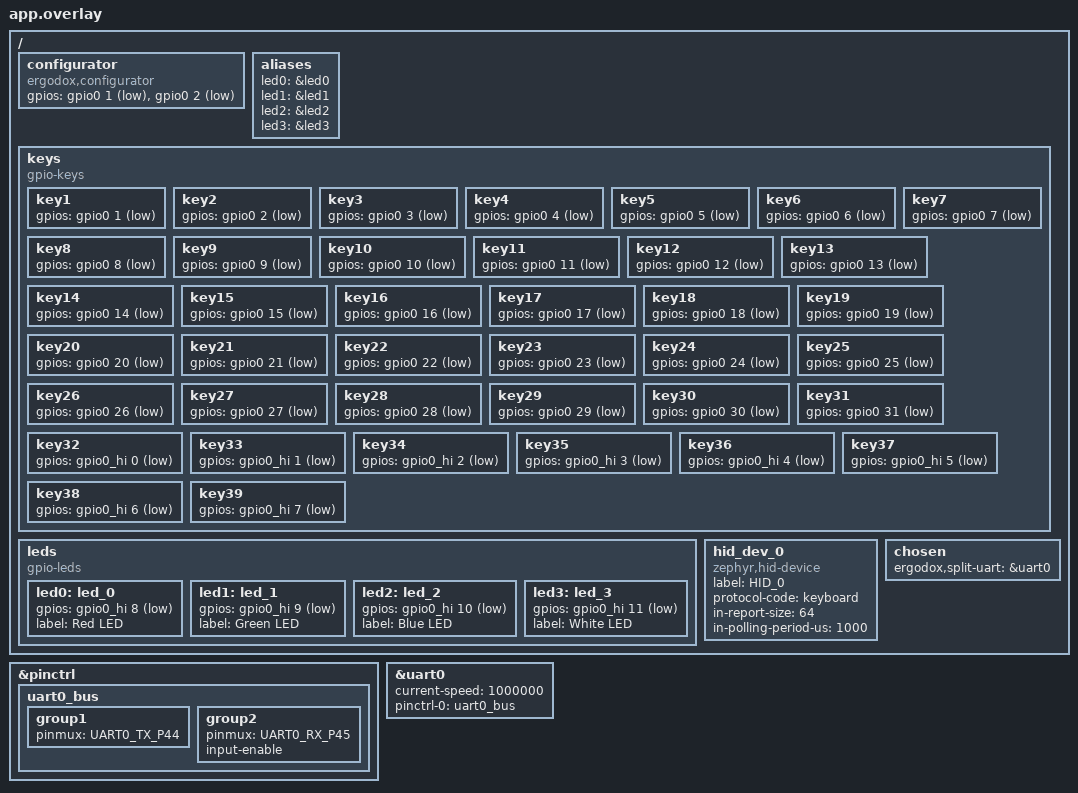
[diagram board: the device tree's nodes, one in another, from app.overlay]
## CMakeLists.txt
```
cmake_minimum_required(VERSION 3.20.0)

set(BOARD rp2350b_core/rp2350b/m33)
set(ERGODOX_SOURCE_DIR "${CMAKE_CURRENT_LIST_DIR}")

# Discover application bindings even when sysbuild uses its image directory.
list(APPEND DTS_ROOT "${ERGODOX_SOURCE_DIR}")

find_package(Zephyr REQUIRED)
project(ergodoxcustom)

include(${ERGODOX_SOURCE_DIR}/cmake/ergodox_application.cmake)
```

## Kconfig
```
mainmenu "Ergodox custom main menu"

choice ERGODOX_KEYBOARD_HAND
    prompt "Keyboard hand"
    default ERGODOX_KEYBOARD_HAND_RIGHT

config ERGODOX_KEYBOARD_HAND_LEFT
    bool "Left hand"
    help
      Build firmware using the left-hand side of the selected layout.

config ERGODOX_KEYBOARD_HAND_RIGHT
    bool "Right hand"
    help
      Build firmware using the right-hand side of the selected layout.

endchoice

config ERGODOX_SPLIT_UART
    bool "Enable split keyboard UART transport"
    default y
    select SERIAL
    select UART_INTERRUPT_DRIVEN
    help
      Enable the UART transport used to forward raw key events from the
      non-USB half to the USB-connected half.

config ERGODOX_SPLIT_UART_BAUDRATE
    int "Split UART baudrate"
    default 1000000
    depends on ERGODOX_SPLIT_UART

config ERGODOX_USB_READY_TIMEOUT_MS
    int "USB ready timeout before falling back to UART"
    default 1500
    help
      Time to wait at boot for the USB HID interface to become ready. If USB
      initialization fails or the interface is not ready before this timeout,
      the firmware acts as the UART-sender half.

choice ERGODOX_KEYBOARD_LAYOUT
    prompt "Factory fallback keyboard layout"
    default ERGODOX_KEYBOARD_LAYOUT_SIMPLE

config ERGODOX_KEYBOARD_LAYOUT_SIMPLE
    bool "Simple layered layout"
    help
      Factory fallback used when NVM has no valid configuration.
      QWERTY-style layout with navigation, symbol, and function layers.

config ERGODOX_KEYBOARD_LAYOUT_CUSTOM
    bool "My custom layout"
    help
      Compiled custom factory fallback used when NVM has no valid configuration.

endchoice

source "Kconfig.zephyr"
```

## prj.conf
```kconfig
CONFIG_USB_DEVICE_STACK_NEXT=y
CONFIG_USBD_HID_SUPPORT=y

CONFIG_GPIO=y

CONFIG_MAIN_STACK_SIZE=4096

CONFIG_LOG=y
CONFIG_LOG_DEFAULT_LEVEL=3

# Stream logs over SWD using RTT channel 0 (Raspberry Pi Debug Probe/OpenOCD).
CONFIG_USE_SEGGER_RTT=y
CONFIG_LOG_BACKEND_RTT=y
CONFIG_LOG_BACKEND_RTT_BUFFER=0
CONFIG_LOG_BACKEND_RTT_MODE_DROP=y
CONFIG_SEGGER_RTT_MODE_NO_BLOCK_SKIP=y
CONFIG_SEGGER_RTT_BUFFER_SIZE_UP=4096

# Keep USB CDC ACM serial initialization disabled
CONFIG_UDC_RPI_PICO=y
CONFIG_USB_CDC_ACM=n
CONFIG_CDC_ACM_SERIAL_INITIALIZE_AT_BOOT=n

CONFIG_UART_CONSOLE=n
CONFIG_LOG_BACKEND_UART=n

CONFIG_NUM_PREEMPT_PRIORITIES=6

CONFIG_ERGODOX_SPLIT_UART=y
CONFIG_ERGODOX_KEYBOARD_LAYOUT_CUSTOM=y

# USB networking is registered only when the boot chord selects configurator mode.
CONFIG_NETWORKING=y
CONFIG_NET_L2_ETHERNET=y
CONFIG_NET_IPV4=y
CONFIG_NET_IPV6=n
CONFIG_NET_TCP=y
CONFIG_NET_UDP=y
CONFIG_NET_DHCPV4_SERVER=y
CONFIG_NET_DHCPV4_SERVER_ADDR_COUNT=1
CONFIG_NET_DHCPV4_SERVER_OPTION_ROUTER=n
CONFIG_NET_DHCPV4_SERVER_OPTION_DNS_ADDRESS=""
CONFIG_HTTP_SERVER=y
CONFIG_HTTP_SERVER_VERSION_2=n
# HTTP/1.1 upload validation reads Content-Type through header capture.
CONFIG_HTTP_SERVER_CAPTURE_HEADERS=y
CONFIG_HTTP_SERVER_CAPTURE_HEADER_COUNT=1
CONFIG_HTTP_SERVER_CAPTURE_HEADER_BUFFER_SIZE=64
# Browsers can keep six connections open to one HTTP origin.
CONFIG_HTTP_SERVER_MAX_CLIENTS=6
CONFIG_NET_MAX_CONTEXTS=12
CONFIG_NET_MAX_CONN=16
CONFIG_ZVFS_POLL_MAX=12
CONFIG_NET_TCP_MAX_SEND_WINDOW_SIZE=2048
CONFIG_NET_TCP_MAX_RECV_WINDOW_SIZE=2048
CONFIG_NET_LOG=y
CONFIG_NET_HTTP_SERVER_LOG_LEVEL_INF=y
CONFIG_HTTP_SERVER_CLIENT_BUFFER_SIZE=1024
CONFIG_NET_PKT_RX_COUNT=16
CONFIG_NET_PKT_TX_COUNT=16
CONFIG_NET_BUF_DATA_SIZE=256
CONFIG_NET_BUF_RX_COUNT=96
CONFIG_NET_BUF_TX_COUNT=96

# One versioned binary configuration record in a dedicated 16 KiB partition.
CONFIG_FLASH=y
CONFIG_FLASH_MAP=y
CONFIG_FLASH_PAGE_LAYOUT=y
CONFIG_NVS=y
```

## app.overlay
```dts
/ {
    configurator {
        compatible = "ergodox,configurator";
        // Hold physical keys 1 and 2 on this half while powering up.
        gpios = <&gpio0 1 (GPIO_ACTIVE_LOW | GPIO_PULL_UP)>,
                <&gpio0 2 (GPIO_ACTIVE_LOW | GPIO_PULL_UP)>;
    };

    aliases {
        led0 = &led0;
        led1 = &led1;
        led2 = &led2;
        led3 = &led3;
    };

    // Define keyboard key GPIOs
    keys: keys {
        compatible = "gpio-keys";

        key1: key1 { gpios = <&gpio0 1 GPIO_ACTIVE_LOW>; };
        key2: key2 { gpios = <&gpio0 2 GPIO_ACTIVE_LOW>; };
        key3: key3 { gpios = <&gpio0 3 GPIO_ACTIVE_LOW>; };
        key4: key4 { gpios = <&gpio0 4 GPIO_ACTIVE_LOW>; };
        key5: key5 { gpios = <&gpio0 5 GPIO_ACTIVE_LOW>; };
        key6: key6 { gpios = <&gpio0 6 GPIO_ACTIVE_LOW>; };
        key7: key7 { gpios = <&gpio0 7 GPIO_ACTIVE_LOW>; };
        key8: key8 { gpios = <&gpio0 8 GPIO_ACTIVE_LOW>; };
        key9: key9 { gpios = <&gpio0 9 GPIO_ACTIVE_LOW>; };
        key10: key10 { gpios = <&gpio0 10 GPIO_ACTIVE_LOW>; };
        key11: key11 { gpios = <&gpio0 11 GPIO_ACTIVE_LOW>; };
        key12: key12 { gpios = <&gpio0 12 GPIO_ACTIVE_LOW>; };
        key13: key13 { gpios = <&gpio0 13 GPIO_ACTIVE_LOW>; };
        key14: key14 { gpios = <&gpio0 14 GPIO_ACTIVE_LOW>; };
        key15: key15 { gpios = <&gpio0 15 GPIO_ACTIVE_LOW>; };
        key16: key16 { gpios = <&gpio0 16 GPIO_ACTIVE_LOW>; };
        key17: key17 { gpios = <&gpio0 17 GPIO_ACTIVE_LOW>; };
        key18: key18 { gpios = <&gpio0 18 GPIO_ACTIVE_LOW>; };
        key19: key19 { gpios = <&gpio0 19 GPIO_ACTIVE_LOW>; };
        key20: key20 { gpios = <&gpio0 20 GPIO_ACTIVE_LOW>; };
        key21: key21 { gpios = <&gpio0 21 GPIO_ACTIVE_LOW>; };
        key22: key22 { gpios = <&gpio0 22 GPIO_ACTIVE_LOW>; };
        key23: key23 { gpios = <&gpio0 23 GPIO_ACTIVE_LOW>; };
        key24: key24 { gpios = <&gpio0 24 GPIO_ACTIVE_LOW>; };
        key25: key25 { gpios = <&gpio0 25 GPIO_ACTIVE_LOW>; };
        key26: key26 { gpios = <&gpio0 26 GPIO_ACTIVE_LOW>; };
        key27: key27 { gpios = <&gpio0 27 GPIO_ACTIVE_LOW>; };
        key28: key28 { gpios = <&gpio0 28 GPIO_ACTIVE_LOW>; };
        key29: key29 { gpios = <&gpio0 29 GPIO_ACTIVE_LOW>; };
        key30: key30 { gpios = <&gpio0 30 GPIO_ACTIVE_LOW>; };
        key31: key31 { gpios = <&gpio0 31 GPIO_ACTIVE_LOW>; };
        key32: key32 { gpios = <&gpio0_hi 0 GPIO_ACTIVE_LOW>; };
        key33: key33 { gpios = <&gpio0_hi 1 GPIO_ACTIVE_LOW>; };
        key34: key34 { gpios = <&gpio0_hi 2 GPIO_ACTIVE_LOW>; };
        key35: key35 { gpios = <&gpio0_hi 3 GPIO_ACTIVE_LOW>; };
        key36: key36 { gpios = <&gpio0_hi 4 GPIO_ACTIVE_LOW>; };
        key37: key37 { gpios = <&gpio0_hi 5 GPIO_ACTIVE_LOW>; };
        key38: key38 { gpios = <&gpio0_hi 6 GPIO_ACTIVE_LOW>; };
        key39: key39 { gpios = <&gpio0_hi 7 GPIO_ACTIVE_LOW>; };
    };

    leds {
        compatible = "gpio-leds";
        led0: led_0 {
            gpios = <&gpio0_hi 8 GPIO_ACTIVE_LOW>;
            label = "Red LED";
        };
        led1: led_1 {
            gpios = <&gpio0_hi 9 GPIO_ACTIVE_LOW>;
            label = "Green LED";
        };
        led2: led_2 {
            gpios = <&gpio0_hi 10 GPIO_ACTIVE_LOW>;
            label = "Blue LED";
        };
        led3: led_3 {
            gpios = <&gpio0_hi 11 GPIO_ACTIVE_LOW>;
            label = "White LED";
        };
    };

    hid_dev_0: hid_dev_0 {
		compatible = "zephyr,hid-device";
		label = "HID_0";
		protocol-code = "keyboard";
		in-report-size = <64>;
		in-polling-period-us = <1000>;
	};


	chosen {
	    ergodox,split-uart = &uart0;
	    // zephyr,console = &uart0;
	    // zephyr,shell-uart = &uart0;
	};
};


&pinctrl {
    uart0_bus: uart0_bus {
        group1 {
            pinmux = <UART0_TX_P44>;
        };
        group2 {
            pinmux = <UART0_RX_P45>;
            input-enable;
        };
    };
};

&uart0 {
    status = "okay";
    current-speed = <1000000>;
    pinctrl-0 = <&uart0_bus>;
    pinctrl-names = "default";
};
```

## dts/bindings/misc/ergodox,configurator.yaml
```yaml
description: Boot chord for entering the ErgoDox configurator
compatible: "ergodox,configurator"
properties:
  gpios:
    type: phandle-array
    required: true
    description: |
      Local GPIO inputs which must all be logically active throughout the boot
      sampling interval. Specify polarity and pull resistors in each GPIO entry.
      These may share pins with keyboard keys. An empty list is not permitted.
```

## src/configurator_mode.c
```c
#include <errno.h>

#include <zephyr/drivers/gpio.h>
#include <zephyr/kernel.h>
#include <zephyr/logging/log.h>

#include "configurator_mode.h"
#include "configurator_network.h"
#include "keyboard_config.h"
#include "keyboard_input_state.h"

LOG_MODULE_REGISTER(configurator);

#define CONFIGURATOR_NODE DT_COMPAT_GET_ANY_STATUS_OKAY(ergodox_configurator)

BUILD_ASSERT(DT_NUM_INST_STATUS_OKAY(ergodox_configurator) <= 1,
    "Only one configurator boot chord may be defined");

#if DT_HAS_COMPAT_STATUS_OKAY(ergodox_configurator)
#define CHORD_GPIO(node_id, prop, idx) GPIO_DT_SPEC_GET_BY_IDX(node_id, prop, idx),
static const struct gpio_dt_spec chord[] = {
    DT_FOREACH_PROP_ELEM(CONFIGURATOR_NODE, gpios, CHORD_GPIO)
};
BUILD_ASSERT(ARRAY_SIZE(chord) > 0, "Configurator chord must not be empty");
#endif

int configurator_mode_requested(bool *requested)
{
    *requested = false;
#if DT_HAS_COMPAT_STATUS_OKAY(ergodox_configurator)
    for (size_t i = 0; i < ARRAY_SIZE(chord); ++i) {
        if (!gpio_is_ready_dt(&chord[i])) {
            return -ENODEV;
        }
        int ret = gpio_pin_configure_dt(&chord[i], GPIO_INPUT);
        if (ret < 0) {
            return ret;
        }
    }

    /* Allow pulls to settle, then require the entire chord for 20 ms. */
    k_sleep(K_MSEC(1));
    for (int sample = 0; sample <= 4; ++sample) {
        for (size_t i = 0; i < ARRAY_SIZE(chord); ++i) {
            int ret = gpio_pin_get_dt(&chord[i]);
            if (ret < 0) {
                return ret;
            }
            if (ret == 0) {
                return 0;
            }
        }
        if (sample < 4) {
            k_sleep(K_MSEC(5));
        }
    }
    *requested = true;
#endif
    return 0;
}

void configurator_mode_run(void)
{
    int ret = keyboard_config_init(true);

    if (ret == 0) {
        ret = keyboard_inputs_start_configurator();
    }
    if (ret == 0) {
        ret = configurator_network_start();
    }

    if (ret != 0) {
        LOG_ERR("Configurator startup failed: %d; reboot to retry", ret);
    }
    for (;;) {
        k_sleep(K_FOREVER);
    }
}
```

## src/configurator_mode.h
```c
#ifndef ERGODOX_CONFIGURATOR_MODE_H
#define ERGODOX_CONFIGURATOR_MODE_H

#include <stdbool.h>

/* Returns zero and the boot decision, or a negative GPIO error. */
int configurator_mode_requested(bool *requested);
/* Placeholder until USB networking and the configuration server are added. */
void configurator_mode_run(void);

#endif
```

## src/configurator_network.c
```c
#include <errno.h>
#include <string.h>
#include <strings.h>

#include <zephyr/device.h>
#include <zephyr/kernel.h>
#include <zephyr/logging/log.h>
#include <zephyr/net/dhcpv4_server.h>
#include <zephyr/net/http/server.h>
#include <zephyr/net/http/service.h>
#include <zephyr/net/net_if.h>
#include <zephyr/usb/usbd.h>

#include "configurator_network.h"
#include "keyboard_config.h"
#include "keyboard_input_state.h"

LOG_MODULE_REGISTER(configurator_network);

#define CONFIGURATOR_ADDRESS "192.168.7.1"

/* A separate identity avoids the host caching the normal keyboard interfaces. */
USBD_DEVICE_DEFINE(configurator_usbd,
    DEVICE_DT_GET(DT_NODELABEL(zephyr_udc0)), 0x2fe3, 0x0008);
USBD_DESC_LANG_DEFINE(configurator_lang);
USBD_DESC_MANUFACTURER_DEFINE(configurator_mfr, "Zephyr");
USBD_DESC_PRODUCT_DEFINE(configurator_product, "Ergodox Configurator");
USBD_DESC_CONFIG_DEFINE(configurator_fs_desc, "Configurator Network");
USBD_CONFIGURATION_DEFINE(configurator_fs_config, 0, 50, &configurator_fs_desc);

static const uint8_t index_html[] = {
#include "configurator_index.html.inc"
};

static struct http_resource_detail_static index_resource = {
    .common = {
        .type = HTTP_RESOURCE_TYPE_STATIC,
        .bitmask_of_supported_http_methods = BIT(HTTP_GET),
        .content_type = "text/html; charset=utf-8",
        .content_encoding = "gzip",
    },
    .static_data = index_html,
    .static_data_len = sizeof(index_html),
};

static uint8_t layout_blob[KEYBOARD_CONFIG_MAX_BLOB_SIZE];

/* HTTP polls an eventfd, a listener, and one descriptor per accepted client. */
BUILD_ASSERT(CONFIG_ZVFS_POLL_MAX >= CONFIG_HTTP_SERVER_MAX_CLIENTS + 2,
    "Socket poll capacity must cover the complete HTTP descriptor set");
BUILD_ASSERT(CONFIG_NET_MAX_CONTEXTS >= CONFIG_HTTP_SERVER_MAX_CLIENTS + 2,
    "Network contexts must cover HTTP clients, listener, and DHCP");
BUILD_ASSERT(CONFIG_NET_MAX_CONN >= CONFIG_HTTP_SERVER_MAX_CLIENTS + 2,
    "Network connection capacity must cover HTTP and DHCP");

static struct http_resource_detail_static layout_resource = {
    .common = {
        .type = HTTP_RESOURCE_TYPE_STATIC,
        .bitmask_of_supported_http_methods = BIT(HTTP_GET),
        .content_type = "application/octet-stream",
    },
    .static_data = layout_blob,
};

static int keys_handler(struct http_client_ctx *client,
    enum http_transaction_status status,
    const struct http_request_ctx *request,
    struct http_response_ctx *response, void *user_data)
{
    /* The dynamic resource holder serializes transactions until completion. */
    static uint8_t snapshot[KEYBOARD_INPUT_BITMAP_SIZE];
    static const struct http_header headers[] = {
        { .name = "Cache-Control", .value = "no-store" },
    };

    ARG_UNUSED(client);
    ARG_UNUSED(request);
    ARG_UNUSED(user_data);
    if (status == HTTP_SERVER_REQUEST_DATA_FINAL) {
        keyboard_input_state_snapshot(snapshot);
        response->headers = headers;
        response->header_count = ARRAY_SIZE(headers);
        response->body = snapshot;
        response->body_len = sizeof(snapshot);
        response->final_chunk = true;
    }
    return 0;
}

static struct http_resource_detail_dynamic keys_resource = {
    .common = {
        .type = HTTP_RESOURCE_TYPE_DYNAMIC,
        .bitmask_of_supported_http_methods = BIT(HTTP_GET),
        .content_type = "application/octet-stream",
    },
    .cb = keys_handler,
};

HTTP_SERVER_REGISTER_HEADER_CAPTURE(configurator_content_type, "Content-Type");

static int upload_handler(struct http_client_ctx *client,
    enum http_transaction_status status,
    const struct http_request_ctx *request,
    struct http_response_ctx *response, void *user_data)
{
    /* One holder per dynamic resource; aborted requests never reach NVM. */
    static uint8_t upload[KEYBOARD_CONFIG_MAX_BLOB_SIZE];
    static size_t used;
    static bool oversized;
    static bool binary_content_type;
    static const struct http_header headers[] = {
        { .name = "Cache-Control", .value = "no-store" },
    };
    const char *body;
    int ret;

    ARG_UNUSED(user_data);
    ARG_UNUSED(client);
    if (status == HTTP_SERVER_TRANSACTION_ABORTED ||
        status == HTTP_SERVER_TRANSACTION_COMPLETE) {
        used = 0;
        oversized = false;
        binary_content_type = false;
        return 0;
    }
    /* HTTP/1.1 exposes captured headers on the first body callback only. */
    for (size_t i = 0; i < request->header_count; ++i) {
        if (strcasecmp(request->headers[i].name, "Content-Type") == 0) {
            binary_content_type =
                strcasecmp(request->headers[i].value, "application/octet-stream") == 0;
        }
    }
    if (request->data_len > sizeof(upload) - used) {
        oversized = true;
    }
    if (!oversized && request->data_len != 0) {
        memcpy(upload + used, request->data, request->data_len);
        used += request->data_len;
    }
    if (status != HTTP_SERVER_REQUEST_DATA_FINAL) { return 0; }

    if (!binary_content_type) {
        response->status = HTTP_415_UNSUPPORTED_MEDIA_TYPE;
        body = "{\"error\":\"Expected application/octet-stream\"}";
    } else if (oversized) {
        response->status = HTTP_413_PAYLOAD_TOO_LARGE;
        body = "{\"error\":\"Layout record is too large\"}";
    } else {
        ret = keyboard_config_import(upload, used);
        if (ret == 0) {
            response->status = HTTP_200_OK;
            body = "{\"saved\":true,\"reboot_required\":true}";
        } else if (ret == -EINVAL || ret == -EBADMSG || ret == -ENOTSUP) {
            response->status = HTTP_400_BAD_REQUEST;
            body = "{\"error\":\"Invalid layout record; nothing saved\"}";
        } else {
            response->status = HTTP_500_INTERNAL_SERVER_ERROR;
            body = "{\"error\":\"NVM save failed; reboot and retry\"}";
            LOG_ERR("Layout upload save failed: %d", ret);
        }
    }
    response->headers = headers;
    response->header_count = ARRAY_SIZE(headers);
    response->body = (const uint8_t *)body;
    response->body_len = strlen(body);
    response->final_chunk = true;
    return 0;
}

static struct http_resource_detail_dynamic upload_resource = {
    .common = {
        .type = HTTP_RESOURCE_TYPE_DYNAMIC,
        .bitmask_of_supported_http_methods = BIT(HTTP_POST),
        .content_type = "application/json",
    },
    .cb = upload_handler,
};

static uint16_t http_port = 80;
HTTP_SERVICE_DEFINE(configurator_http, CONFIGURATOR_ADDRESS, &http_port,
    CONFIG_HTTP_SERVER_MAX_CLIENTS, CONFIG_HTTP_SERVER_MAX_CLIENTS, NULL, NULL, NULL);
HTTP_RESOURCE_DEFINE(configurator_index, configurator_http, "/", &index_resource);
HTTP_RESOURCE_DEFINE(configurator_layout, configurator_http, "/api/layout", &layout_resource);
HTTP_RESOURCE_DEFINE(configurator_keys, configurator_http, "/api/keys", &keys_resource);
HTTP_RESOURCE_DEFINE(configurator_upload, configurator_http, "/api/layout/import", &upload_resource);

static void configurator_usb_message(struct usbd_context *const ctx,
    const struct usbd_msg *const msg)
{
    int ret = 0;

    if (!usbd_can_detect_vbus(ctx)) {
        return;
    }
    if (msg->type == USBD_MSG_VBUS_READY) {
        ret = usbd_enable(ctx);
    } else if (msg->type == USBD_MSG_VBUS_REMOVED) {
        ret = usbd_disable(ctx);
    }
    if (ret != 0) {
        LOG_ERR("Configurator USB state change failed: %d", ret);
    }
}

static int configure_ipv4(void)
{
    const struct device *dev = DEVICE_DT_GET(DT_NODELABEL(configurator_eth));
    struct net_if *iface;
    struct net_in_addr address, netmask, pool;
    int ret;

    if (!device_is_ready(dev)) {
        return -ENODEV;
    }
    iface = net_if_lookup_by_dev(dev);
    if (iface == NULL) {
        return -ENODEV;
    }
    net_addr_pton(NET_AF_INET, CONFIGURATOR_ADDRESS, &address);
    net_addr_pton(NET_AF_INET, "255.255.255.0", &netmask);
    net_addr_pton(NET_AF_INET, "192.168.7.2", &pool);
    if (net_if_ipv4_addr_add(iface, &address, NET_ADDR_MANUAL, 0) == NULL) {
        return -ENOMEM;
    }
    if (!net_if_ipv4_set_netmask_by_addr(iface, &address, &netmask)) {
        return -EINVAL;
    }
    ret = net_if_up(iface);
    if (ret < 0 && ret != -EALREADY) {
        return ret;
    }
    return net_dhcpv4_server_start(iface, &pool);
}

int configurator_network_start(void)
{
    int ret;

    /* Configuration is immutable until reboot; all clients share this snapshot. */
    ret = keyboard_config_export(layout_blob, sizeof(layout_blob),
        &layout_resource.static_data_len);
    if (ret != 0) {
        LOG_ERR("Failed to export current layout: %d", ret);
        return ret;
    }
    ret = configure_ipv4();
    if (ret != 0) {
        LOG_ERR("Configurator IPv4/DHCP initialization failed: %d", ret);
        return ret;
    }
    ret = http_server_start();
    if (ret != 0) {
        LOG_ERR("Configurator HTTP startup failed: %d", ret);
        return ret;
    }
    ret = usbd_add_descriptor(&configurator_usbd, &configurator_lang);
    if (ret != 0) {
        return ret;
    }
    ret = usbd_add_descriptor(&configurator_usbd, &configurator_mfr);
    if (ret != 0) {
        return ret;
    }
    ret = usbd_add_descriptor(&configurator_usbd, &configurator_product);
    if (ret != 0) {
        return ret;
    }
    ret = usbd_add_configuration(&configurator_usbd, USBD_SPEED_FS,
        &configurator_fs_config);
    if (ret != 0) {
        return ret;
    }
    /* Register only networking: no HID or serial interfaces in this mode. */
    ret = usbd_register_class(&configurator_usbd, "cdc_ncm_0", USBD_SPEED_FS, 1);
    if (ret != 0) {
        return ret;
    }
    ret = usbd_device_set_code_triple(&configurator_usbd, USBD_SPEED_FS,
        USB_BCC_MISCELLANEOUS, 0x02, 0x01);
    if (ret != 0) {
        return ret;
    }
    ret = usbd_msg_register_cb(&configurator_usbd, configurator_usb_message);
    if (ret != 0) {
        return ret;
    }
    ret = usbd_init(&configurator_usbd);
    if (ret != 0) {
        return ret;
    }
    if (!usbd_can_detect_vbus(&configurator_usbd)) {
        ret = usbd_enable(&configurator_usbd);
        if (ret != 0) {
            return ret;
        }
    }
    LOG_INF("Configurator ready at http://" CONFIGURATOR_ADDRESS);
    return 0;
}
```

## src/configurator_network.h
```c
#ifndef ERGODOX_CONFIGURATOR_NETWORK_H
#define ERGODOX_CONFIGURATOR_NETWORK_H

/* Start the USB network, DHCP server, and read-only layout HTTP service. */
int configurator_network_start(void);

#endif
```

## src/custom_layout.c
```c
#include "keyboard_layout.h"

/* Generated layout: custom - 38 keys per half). */
static const struct keyboard_action custom_layers[KEYBOARD_HAND_COUNT][KEYBOARD_MAX_LAYERS][KEYBOARD_KEY_COUNT] = {
    [KEYBOARD_HAND_RIGHT] = {
        [KEYBOARD_LAYER_BASE] = {
            [0] = KB_MOD(HID_KBD_MODIFIER_RIGHT_ALT, HID_KEY_RIGHTBRACE),
            [1] = KB_MOD(HID_KBD_MODIFIER_LEFT_UI, HID_KEY_PAGEUP),
            [2] = KB_KEY(HID_KEY_HOME),
            [3] = KB_KEY(HID_KEY_6),
            [4] = KB_KEY(HID_KEY_Y),
            [5] = KB_KEY(HID_KEY_H),
            [6] = KB_KEY(HID_KEY_N),
            [7] = KB_KEY(HID_KEY_7),
            [8] = KB_KEY(HID_KEY_U),
            [9] = KB_KEY(HID_KEY_J),
            [10] = KB_KEY(HID_KEY_M),
            [11] = KB_MOD(HID_KBD_MODIFIER_RIGHT_ALT, 0),
            [12] = KB_KEY(HID_KEY_8),
            [13] = KB_KEY(HID_KEY_I),
            [14] = KB_KEY(HID_KEY_K),
            [15] = KB_KEY(HID_KEY_COMMA),
            [16] = KB_KEY(HID_KEY_LEFT),
            [17] = KB_KEY(HID_KEY_9),
            [18] = KB_KEY(HID_KEY_O),
            [19] = KB_KEY(HID_KEY_L),
            [20] = KB_KEY(HID_KEY_DOT),
            [21] = KB_KEY(HID_KEY_DOWN),
            [22] = KB_KEY(HID_KEY_0),
            [23] = KB_KEY(HID_KEY_P),
            [24] = KB_KEY(HID_KEY_SEMICOLON),
            [25] = KB_KEY(HID_KEY_SLASH),
            [26] = KB_KEY(HID_KEY_UP),
            [27] = KB_KEY(HID_KEY_RIGHT),
            [28] = KB_MOD(HID_KBD_MODIFIER_RIGHT_SHIFT, 0),
            [29] = KB_KEY(HID_KEY_EQUAL),
            [30] = KB_KEY(HID_KEY_LEFTBRACE),
            [31] = KB_KEY(HID_KEY_BACKSPACE),
            [33] = KB_MO(KEYBOARD_LAYER_SYMBOL),
            [34] = KB_DF(KEYBOARD_LAYER_NAV),
            [35] = KB_TG(KEYBOARD_LAYER_NAV),
            [36] = KB_MO(KEYBOARD_LAYER_SYMBOL),
            [37] = KB_KEY(HID_KEY_ENTER),
        },
        [KEYBOARD_LAYER_NAV] = {
            [3] = KB_KEY(HID_KEY_F6),
            [5] = KB_KEY(HID_KEY_LEFT),
            [7] = KB_KEY(HID_KEY_F7),
            [9] = KB_KEY(HID_KEY_DOWN),
            [12] = KB_KEY(HID_KEY_F8),
            [14] = KB_KEY(HID_KEY_UP),
            [17] = KB_KEY(HID_KEY_F9),
            [19] = KB_KEY(HID_KEY_RIGHT),
            [22] = KB_KEY(HID_KEY_F10),
            [30] = KB_KEY(HID_KEY_F12),
            [31] = KB_KEY(HID_KEY_F11),
            [32] = KB_KEY(HID_KEY_A),
            [34] = KB_DF(KEYBOARD_LAYER_BASE),
        },
        [KEYBOARD_LAYER_SYMBOL] = {
            [9] = KB_MOD(HID_KBD_MODIFIER_LEFT_SHIFT, HID_KEY_RIGHTBRACE),
            [14] = KB_MOD(HID_KBD_MODIFIER_RIGHT_ALT, HID_KEY_6),
            [17] = KB_CONSUMER(HID_CONSUMER_VOLUME_DECREMENT),
            [19] = KB_KEY(HID_KEY_RIGHTBRACE),
            [22] = KB_CONSUMER(HID_CONSUMER_VOLUME_INCREMENT),
            [24] = KB_MOD(HID_KBD_MODIFIER_LEFT_SHIFT, HID_KEY_APOSTROPHE),
        },
        [KEYBOARD_LAYER_FN] = {
            [8] = KB_KEY(HID_KEY_KP_7),
            [9] = KB_KEY(HID_KEY_KP_4),
            [10] = KB_KEY(HID_KEY_KP_1),
            [11] = KB_KEY(HID_KEY_KP_0),
            [12] = KB_KEY(HID_KEY_KPSLASH),
            [13] = KB_KEY(HID_KEY_KP_8),
            [14] = KB_KEY(HID_KEY_KP_5),
            [15] = KB_KEY(HID_KEY_KP_2),
            [16] = KB_KEY(ERGODOX_HID_KEY_KP_DOT),
            [17] = KB_KEY(HID_KEY_KPASTERISK),
            [18] = KB_KEY(HID_KEY_KP_9),
            [19] = KB_KEY(HID_KEY_KP_6),
            [20] = KB_KEY(HID_KEY_KP_3),
            [34] = KB_DF(KEYBOARD_LAYER_BASE),
        },
    },
    [KEYBOARD_HAND_LEFT] = {
        [KEYBOARD_LAYER_BASE] = {
            [1] = KB_KEY(HID_KEY_X),
            [2] = KB_KEY(HID_KEY_S),
            [3] = KB_KEY(HID_KEY_W),
            [4] = KB_KEY(HID_KEY_2),
            [5] = KB_MO(KEYBOARD_LAYER_NAV),
            [6] = KB_KEY(HID_KEY_C),
            [7] = KB_KEY(HID_KEY_D),
            [8] = KB_KEY(HID_KEY_E),
            [9] = KB_KEY(HID_KEY_3),
            [10] = KB_MOD(HID_KBD_MODIFIER_LEFT_ALT, 0),
            [11] = KB_KEY(HID_KEY_V),
            [12] = KB_KEY(HID_KEY_F),
            [13] = KB_KEY(HID_KEY_R),
            [14] = KB_KEY(HID_KEY_4),
            [15] = KB_KEY(HID_KEY_B),
            [16] = KB_KEY(HID_KEY_G),
            [17] = KB_KEY(HID_KEY_T),
            [18] = KB_KEY(HID_KEY_5),
            [19] = KB_KEY(HID_KEY_END),
            [20] = KB_MOD(HID_KBD_MODIFIER_LEFT_UI, HID_KEY_PAGEDOWN),
            [21] = KB_MOD(HID_KBD_MODIFIER_RIGHT_ALT, HID_KEY_LEFTBRACE),
            [22] = KB_MOD(HID_KBD_MODIFIER_LEFT_CTRL, 0),
            [23] = KB_MOD(HID_KBD_MODIFIER_LEFT_SHIFT, 0),
            [24] = KB_KEY(HID_KEY_GRAVE),
            [25] = KB_KEY(HID_KEY_TAB),
            [26] = KB_KEY(HID_KEY_ESC),
            [27] = KB_MOD(HID_KBD_MODIFIER_RIGHT_ALT, ERGODOX_HID_KEY_NON_US_BACKSLASH),
            [28] = KB_KEY(HID_KEY_Z),
            [29] = KB_KEY(HID_KEY_A),
            [30] = KB_KEY(HID_KEY_Q),
            [31] = KB_KEY(HID_KEY_1),
            [32] = KB_KEY(HID_KEY_SPACE),
            [33] = KB_KEY(HID_KEY_DELETE),
            [34] = KB_MOD(HID_KBD_MODIFIER_LEFT_UI, 0),
            [36] = KB_DF(KEYBOARD_LAYER_FN),
            [37] = KB_MOD(HID_KBD_MODIFIER_LEFT_UI, 0),
        },
        [KEYBOARD_LAYER_NAV] = {
            [4] = KB_KEY(HID_KEY_F2),
            [9] = KB_KEY(HID_KEY_F3),
            [14] = KB_KEY(HID_KEY_F4),
            [18] = KB_KEY(HID_KEY_F5),
            [26] = KB_KEY(HID_KEY_GRAVE),
            [31] = KB_KEY(HID_KEY_F1),
        },
        [KEYBOARD_LAYER_SYMBOL] = {
            [2] = KB_MOD(HID_KBD_MODIFIER_LEFT_SHIFT, ERGODOX_HID_KEY_NON_US_BACKSLASH),
            [7] = KB_MOD(HID_KBD_MODIFIER_RIGHT_ALT, ERGODOX_HID_KEY_NON_US_BACKSLASH),
            [12] = KB_MOD(HID_KBD_MODIFIER_RIGHT_ALT, HID_KEY_BACKSLASH),
            [18] = KB_KEY(HID_KEY_MINUS),
            [20] = KB_KEY(HID_KEY_END),
            [21] = KB_MOD(HID_KBD_MODIFIER_RIGHT_ALT, HID_KEY_RIGHTBRACE),
            [29] = KB_KEY(ERGODOX_HID_KEY_NON_US_BACKSLASH),
        },
        [KEYBOARD_LAYER_FN] = {
        },
    },
};

static const struct keyboard_layout custom_layout = {
    .name = "custom",
    .layer_count = KEYBOARD_LAYER_COUNT,
    .default_layer = KEYBOARD_LAYER_BASE,
    .layers = &custom_layers,
};
```

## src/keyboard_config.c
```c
#include <errno.h>
#include <string.h>

#include "keyboard_config.h"

static uint16_t get16(const uint8_t *p)
{
    return (uint16_t)p[0] | (uint16_t)p[1] << 8;
}

static uint32_t get32(const uint8_t *p)
{
    return (uint32_t)p[0] | (uint32_t)p[1] << 8 |
        (uint32_t)p[2] << 16 | (uint32_t)p[3] << 24;
}

static void put32(uint8_t *p, uint32_t value)
{
    for (int i = 0; i < 4; ++i) {
        p[i] = (uint8_t)(value >> (8 * i));
    }
}

/* IEEE CRC-32 over header and payload with bytes 60..63 treated as zero.
 * Used only during load/save, never in the key-event path. */
static uint32_t blob_crc(const uint8_t *blob, size_t length)
{
    uint32_t crc = UINT32_MAX;

    for (size_t i = 0; i < length; ++i) {
        crc ^= (i >= 60 && i < 64) ? 0 : blob[i];
        for (int bit = 0; bit < 8; ++bit) {
            crc = (crc >> 1) ^ (0xedb88320U & (0U - (crc & 1U)));
        }
    }
    return ~crc;
}

static bool valid_action(const struct keyboard_action *a, uint8_t layers, const struct keyboard_macro *macros)
{
    struct keyboard_action canonical = { .type = a->type };

    switch (a->type) {
    case KEYBOARD_ACTION_TRANSPARENT:
    case KEYBOARD_ACTION_NONE:
        break;
    case KEYBOARD_ACTION_KEY:
        if (a->keycode > 101) { return false; }
        canonical.keycode = a->keycode;
        canonical.modifier = a->modifier;
        break;
    case KEYBOARD_ACTION_MACRO:
        if (a->usage >= KEYBOARD_MACRO_COUNT || macros[a->usage].count == 0) { return false; }
        canonical.usage = a->usage;
        break;
    case KEYBOARD_ACTION_CONSUMER:
        if (a->usage > 0x3ff) { return false; }
        canonical.usage = a->usage;
        break;
    case KEYBOARD_ACTION_SYSTEM:
        if (a->usage != 0 && (a->usage < HID_SYSTEM_POWER_DOWN ||
            a->usage > HID_SYSTEM_WAKE_UP)) { return false; }
        canonical.usage = a->usage;
        break;
    case KEYBOARD_ACTION_MOUSE_BUTTON:
        if (a->usage & ~0x1fU) { return false; }
        canonical.usage = a->usage;
        break;
    case KEYBOARD_ACTION_MOUSE_MOVE:
        if (a->x == INT8_MIN || a->y == INT8_MIN) { return false; }
        canonical.x = a->x;
        canonical.y = a->y;
        break;
    case KEYBOARD_ACTION_MOUSE_WHEEL:
        if (a->y == INT8_MIN) { return false; }
        canonical.y = a->y;
        break;
    case KEYBOARD_ACTION_LIGHTING:
        if (a->usage > KEYBOARD_LIGHTING_BRIGHTNESS_DOWN) { return false; }
        canonical.usage = a->usage;
        break;
    case KEYBOARD_ACTION_LAYER_MOMENTARY:
    case KEYBOARD_ACTION_LAYER_TOGGLE:
    case KEYBOARD_ACTION_LAYER_DEFAULT:
        if (a->layer >= layers) { return false; }
        canonical.layer = a->layer;
        break;
    default:
        return false;
    }
    return memcmp(a, &canonical, sizeof(*a)) == 0;
}

static bool valid_display_layout(const uint8_t *name, size_t capacity, bool allow_empty)
{
    for (size_t i = 0; i < capacity; ++i) {
        uint8_t c = name[i];
        if (c == 0) { return i != 0 || allow_empty; }
        if (!((c >= 'a' && c <= 'z') || (c >= '0' && c <= '9') ||
            (i != 0 && (c == '-' || c == '_')))) { return false; }
    }
    return false;
}

int keyboard_config_validate(const struct keyboard_config *config)
{
    if (config == NULL || config->layer_count == 0 ||
        config->layer_count > KEYBOARD_MAX_LAYERS ||
        config->default_layer >= config->layer_count ||
        memchr(config->name, '\0', sizeof(config->name)) == NULL ||
        !valid_display_layout((const uint8_t *)config->display_layout, sizeof(config->display_layout), true)) {
        return -EINVAL;
    }
    for (int i = 0; i < KEYBOARD_MACRO_COUNT; ++i) {
        const struct keyboard_macro *macro = &config->macros[i];
        if (macro->count > KEYBOARD_MACRO_MAX_STEPS) { return -EINVAL; }
        for (int j = 0; j < KEYBOARD_MACRO_MAX_STEPS; ++j) {
            const struct keyboard_macro_step *step = &macro->steps[j];
            if (step->keycode > 101 || step->delay_ms > KEYBOARD_MACRO_MAX_DELAY_MS ||
                (j >= macro->count && (step->modifier || step->keycode || step->delay_ms))) {
                return -EINVAL;
            }
        }
    }
    for (int hand = 0; hand < KEYBOARD_HAND_COUNT; ++hand) {
        for (int layer = 0; layer < config->layer_count; ++layer) {
            for (int key = 0; key < KEYBOARD_KEY_COUNT; ++key) {
                if (!valid_action(&config->actions[hand][layer][key],
                    config->layer_count, config->macros)) {
                    return -EINVAL;
                }
            }
        }
    }
    return 0;
}

static struct keyboard_action decode_action(const uint8_t *p)
{
    struct keyboard_action a = { .type = p[0], .modifier = p[1] };

    /* Explicit wire byte order; do not serialize the native union. */
    if (a.type == KEYBOARD_ACTION_MOUSE_MOVE || a.type == KEYBOARD_ACTION_MOUSE_WHEEL) {
        a.x = p[2] < 128 ? p[2] : (int)p[2] - 256;
        a.y = p[3] < 128 ? p[3] : (int)p[3] - 256;
    } else if (a.type == KEYBOARD_ACTION_KEY ||
        (a.type >= KEYBOARD_ACTION_LAYER_MOMENTARY && a.type <= KEYBOARD_ACTION_LAYER_DEFAULT)) {
        a.keycode = p[2];
        a.layer = p[3];
    } else {
        a.usage = get16(p + 2);
    }
    return a;
}

int keyboard_config_encode(const struct keyboard_config *config,
    uint8_t *blob, size_t capacity, size_t *length)
{
    size_t offset = KEYBOARD_CONFIG_HEADER_SIZE;
    size_t size;
    int ret = keyboard_config_validate(config);

    if (ret != 0 || blob == NULL || length == NULL) {
        return -EINVAL;
    }
    size = KEYBOARD_CONFIG_HEADER_SIZE +
        KEYBOARD_HAND_COUNT * config->layer_count * KEYBOARD_KEY_COUNT * 4;
    size += KEYBOARD_CONFIG_MACRO_BANK_SIZE + KEYBOARD_CONFIG_DISPLAY_LAYOUT_SIZE;
    if (capacity < size) { return -ENOSPC; }
    memset(blob, 0, size);
    memcpy(blob, "EKCF", 4);
    blob[4] = KEYBOARD_CONFIG_VERSION;
    blob[6] = KEYBOARD_CONFIG_HEADER_SIZE;
    put32(blob + 8, size);
    blob[12] = config->layer_count;
    blob[13] = config->default_layer;
    blob[14] = KEYBOARD_HAND_COUNT;
    blob[15] = KEYBOARD_KEY_COUNT;
    memcpy(blob + 16, config->name, strlen(config->name));
    for (int hand = 0; hand < KEYBOARD_HAND_COUNT; ++hand) {
        for (int layer = 0; layer < config->layer_count; ++layer) {
            for (int key = 0; key < KEYBOARD_KEY_COUNT; ++key) {
                const struct keyboard_action *a = &config->actions[hand][layer][key];
                blob[offset] = a->type;
                blob[offset + 1] = a->modifier;
                if (a->type == KEYBOARD_ACTION_MOUSE_MOVE || a->type == KEYBOARD_ACTION_MOUSE_WHEEL) {
                    blob[offset + 2] = (uint8_t)a->x;
                    blob[offset + 3] = (uint8_t)a->y;
                } else if (a->type == KEYBOARD_ACTION_KEY ||
                    (a->type >= KEYBOARD_ACTION_LAYER_MOMENTARY && a->type <= KEYBOARD_ACTION_LAYER_DEFAULT)) {
                    blob[offset + 2] = a->keycode;
                    blob[offset + 3] = a->layer;
                } else {
                    blob[offset + 2] = a->usage & 0xff;
                    blob[offset + 3] = a->usage >> 8;
                }
                offset += 4;
            }
        }
    }
    for (int i = 0; i < KEYBOARD_MACRO_COUNT; ++i) {
        const struct keyboard_macro *macro = &config->macros[i];
        blob[offset] = macro->count;
        offset += 4;
        for (int j = 0; j < KEYBOARD_MACRO_MAX_STEPS; ++j) {
            const struct keyboard_macro_step *step = &macro->steps[j];
            blob[offset] = step->modifier;
            blob[offset + 1] = step->keycode;
            blob[offset + 2] = step->delay_ms & 0xff;
            blob[offset + 3] = step->delay_ms >> 8;
            offset += 4;
        }
    }
    const char *locale = config->display_layout[0] ? config->display_layout : KEYBOARD_CONFIG_DEFAULT_DISPLAY_LAYOUT;
    memcpy(blob + offset, locale, strlen(locale));
    put32(blob + 60, blob_crc(blob, size));
    *length = size;
    return 0;
}

int keyboard_config_decode(const uint8_t *blob, size_t length,
    struct keyboard_config *config)
{
    size_t expected, offset = KEYBOARD_CONFIG_HEADER_SIZE;
    uint8_t layers;

    if (blob == NULL || config == NULL || length < KEYBOARD_CONFIG_HEADER_SIZE ||
        length > KEYBOARD_CONFIG_MAX_BLOB_SIZE) { return -EINVAL; }
    uint16_t version = get16(blob + 4);
    if (memcmp(blob, "EKCF", 4) != 0 || (version != 1 && version != 2 && version != 3 && version != 4 && version != KEYBOARD_CONFIG_VERSION) ||
        get16(blob + 6) != KEYBOARD_CONFIG_HEADER_SIZE) { return -ENOTSUP; }
    layers = blob[12];
    expected = KEYBOARD_CONFIG_HEADER_SIZE + KEYBOARD_HAND_COUNT * layers * KEYBOARD_KEY_COUNT * 4;
    if (version >= 3) { expected += KEYBOARD_CONFIG_MACRO_BANK_SIZE; }
    if (version >= 5) { expected += KEYBOARD_CONFIG_DISPLAY_LAYOUT_SIZE; }
    if (layers == 0 || layers > KEYBOARD_MAX_LAYERS || blob[13] >= layers ||
        blob[14] != KEYBOARD_HAND_COUNT || blob[15] != KEYBOARD_KEY_COUNT ||
        length != expected || get32(blob + 8) != length ||
        memchr(blob + 16, '\0', KEYBOARD_CONFIG_NAME_SIZE) == NULL) { return -EINVAL; }
    if (version == 1 || version >= 4) {
        for (int i = 48; i < 60; ++i) {
            if (blob[i] != 0) { return -EINVAL; }
        }
    }
    const uint8_t *locale = (const uint8_t *)KEYBOARD_CONFIG_DEFAULT_DISPLAY_LAYOUT;
    if (version >= 5) {
        locale = blob + length - KEYBOARD_CONFIG_DISPLAY_LAYOUT_SIZE;
        if (!valid_display_layout(locale, KEYBOARD_CONFIG_DISPLAY_LAYOUT_SIZE, false)) { return -EINVAL; }
    } else if (version == 2 || version == 3) {
        locale = blob + 48;
        if (!valid_display_layout(locale, 12, false)) { return -EINVAL; }
    }
    if (get32(blob + 60) != blob_crc(blob, length)) { return -EBADMSG; }
    /* Decode/validate the small macro bank before touching the destination. */
    struct keyboard_macro macros[KEYBOARD_MACRO_COUNT] = {0};
    size_t actions_end = KEYBOARD_CONFIG_HEADER_SIZE + KEYBOARD_HAND_COUNT * layers * KEYBOARD_KEY_COUNT * 4;
    if (version >= 3) {
        size_t macro_offset = actions_end;
        for (int i = 0; i < KEYBOARD_MACRO_COUNT; ++i) {
            struct keyboard_macro *macro = &macros[i];
            macro->count = blob[macro_offset];
            if (macro->count > KEYBOARD_MACRO_MAX_STEPS || blob[macro_offset + 1] ||
                blob[macro_offset + 2] || blob[macro_offset + 3]) { return -EINVAL; }
            macro_offset += 4;
            for (int j = 0; j < KEYBOARD_MACRO_MAX_STEPS; ++j) {
                struct keyboard_macro_step *step = &macro->steps[j];
                step->modifier = blob[macro_offset];
                step->keycode = blob[macro_offset + 1];
                step->delay_ms = get16(blob + macro_offset + 2);
                if (step->keycode > 101 || step->delay_ms > KEYBOARD_MACRO_MAX_DELAY_MS ||
                    (j >= macro->count && (step->modifier || step->keycode || step->delay_ms))) { return -EINVAL; }
                macro_offset += 4;
            }
        }
    }
    /* Validate the entire candidate before modifying any destination data. */
    for (size_t i = KEYBOARD_CONFIG_HEADER_SIZE; i < actions_end; i += 4) {
        struct keyboard_action a = decode_action(blob + i);
        if (!valid_action(&a, layers, macros)) { return -EINVAL; }
    }
    memset(config, 0, sizeof(*config));
    memcpy(config->name, blob + 16, sizeof(config->name));
    memcpy(config->macros, macros, sizeof(macros));
    config->layer_count = layers;
    config->default_layer = blob[13];
    strcpy(config->display_layout, (const char *)locale);
    for (int hand = 0; hand < KEYBOARD_HAND_COUNT; ++hand) {
        for (int layer = 0; layer < layers; ++layer) {
            for (int key = 0; key < KEYBOARD_KEY_COUNT; ++key) {
                config->actions[hand][layer][key] = decode_action(blob + offset);
                offset += 4;
            }
        }
    }
    return 0;
}
```

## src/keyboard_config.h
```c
#ifndef ERGODOX_KEYBOARD_CONFIG_H
#define ERGODOX_KEYBOARD_CONFIG_H

#include <stddef.h>
#include "keyboard_layout.h"

#define KEYBOARD_CONFIG_NAME_SIZE 32
#define KEYBOARD_CONFIG_HEADER_SIZE 64
#define KEYBOARD_CONFIG_VERSION 5
#define KEYBOARD_CONFIG_DISPLAY_LAYOUT_SIZE 128
#define KEYBOARD_CONFIG_DEFAULT_DISPLAY_LAYOUT "qwerty"
#define KEYBOARD_CONFIG_MACRO_SLOT_SIZE (4 + KEYBOARD_MACRO_MAX_STEPS * 4)
#define KEYBOARD_CONFIG_MACRO_BANK_SIZE (KEYBOARD_MACRO_COUNT * KEYBOARD_CONFIG_MACRO_SLOT_SIZE)
#define KEYBOARD_CONFIG_MAX_BLOB_SIZE (KEYBOARD_CONFIG_HEADER_SIZE + \
    KEYBOARD_HAND_COUNT * KEYBOARD_MAX_LAYERS * KEYBOARD_KEY_COUNT * 4 + \
    KEYBOARD_CONFIG_MACRO_BANK_SIZE + KEYBOARD_CONFIG_DISPLAY_LAYOUT_SIZE)

/* Owned RAM data; keyboard_layout is a read-only view of these arrays. */
struct keyboard_config {
    char name[KEYBOARD_CONFIG_NAME_SIZE];
    uint8_t layer_count;
    uint8_t default_layer;
    /* UI identifier only. Empty RAM values encode as qwerty. */
    char display_layout[KEYBOARD_CONFIG_DISPLAY_LAYOUT_SIZE];
    struct keyboard_macro macros[KEYBOARD_MACRO_COUNT];
    struct keyboard_action actions[KEYBOARD_HAND_COUNT][KEYBOARD_MAX_LAYERS][KEYBOARD_KEY_COUNT];
};

int keyboard_config_validate(const struct keyboard_config *config);
int keyboard_config_encode(const struct keyboard_config *config,
    uint8_t *blob, size_t capacity, size_t *length);
/* Failure leaves the destination unchanged. Unknown versions are rejected. */
int keyboard_config_decode(const uint8_t *blob, size_t length,
    struct keyboard_config *config);

/* Initialize before accepting key events. Only configuration mode may save. */
int keyboard_config_init(bool configuration_mode);
const struct keyboard_layout *keyboard_config_layout(void);
/* Read-only snapshot of the active RAM configuration, in the versioned format. */
int keyboard_config_export(uint8_t *blob, size_t capacity, size_t *length);
/* Persists a candidate for next boot; never modifies the live runtime table. */
int keyboard_config_save(const struct keyboard_config *config);
/* Validate a complete binary upload and persist it for the next boot. */
int keyboard_config_import(const uint8_t *blob, size_t length);

#endif
```

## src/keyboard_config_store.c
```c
#include <errno.h>
#include <string.h>

#include <zephyr/drivers/flash.h>
#include <zephyr/kernel.h>
#include <zephyr/kvss/nvs.h>
#include <zephyr/logging/log.h>
#include <zephyr/storage/flash_map.h>

#include "keyboard_config.h"

LOG_MODULE_REGISTER(keyboard_config);

#define CONFIG_RECORD_ID 1

static struct keyboard_config active;
static struct keyboard_layout active_layout;
static struct nvs_fs storage;
static uint8_t blob[KEYBOARD_CONFIG_MAX_BLOB_SIZE];
static bool writes_allowed;
K_MUTEX_DEFINE(config_store_lock);
K_MUTEX_DEFINE(config_import_lock);

static int mount_storage(void)
{
    const struct flash_area *area;
    struct flash_pages_info page;
    int ret;

    ret = flash_area_open(PARTITION_ID(keyboard_config_partition), &area);
    if (ret != 0) { return ret; }
    storage.flash_device = area->fa_dev;
    storage.offset = area->fa_off;
    if (!device_is_ready(storage.flash_device)) {
        flash_area_close(area);
        return -ENODEV;
    }
    ret = flash_get_page_info_by_offs(storage.flash_device, storage.offset, &page);
    if (ret == 0) {
        if (page.size != 4096 || area->fa_size != 4 * page.size ||
            page.start_offset != storage.offset) {
            ret = -EINVAL;
        } else {
            storage.sector_size = page.size;
            storage.sector_count = 4;
        }
    }
    flash_area_close(area);
    if (ret != 0) { return ret; }
    return nvs_mount(&storage);
}

int keyboard_config_init(bool configuration_mode)
{
    const struct keyboard_layout *factory = keyboard_layout_get_selected();
    int ret;
    ssize_t length;

    writes_allowed = configuration_mode;
    memset(&active, 0, sizeof(active));
    strncpy(active.name, factory->name, sizeof(active.name) - 1);
    active.layer_count = factory->layer_count;
    active.default_layer = factory->default_layer;
    strcpy(active.display_layout, KEYBOARD_CONFIG_DEFAULT_DISPLAY_LAYOUT);
    memcpy(active.actions, *factory->layers, sizeof(active.actions));
    if (factory->macros != NULL) { memcpy(active.macros, factory->macros, sizeof(active.macros)); }
    ret = keyboard_config_validate(&active);
    if (ret != 0) {
        LOG_ERR("Invalid compiled factory configuration");
        return ret;
    }

    ret = mount_storage();
    if (ret == 0) {
        length = nvs_read(&storage, CONFIG_RECORD_ID, blob, sizeof(blob));
        ret = length < 0 ? (int)length : keyboard_config_decode(blob, length, &active);
    }
    if (ret != 0) {
        LOG_WRN("Using factory configuration (NVM unavailable or invalid: %d)", ret);
    } else {
        LOG_INF("Loaded configuration from NVM");
    }
    active_layout = (struct keyboard_layout) {
        .name = active.name,
        .layer_count = active.layer_count,
        .default_layer = active.default_layer,
        .layers = &active.actions,
        .macros = active.macros,
    };
    LOG_INF("Configuration: %s, %u layers, %u-byte actions", active.name,
        active.layer_count, (unsigned int)sizeof(struct keyboard_action));
    return 0;
}

const struct keyboard_layout *keyboard_config_layout(void)
{
    return &active_layout;
}

int keyboard_config_export(uint8_t *output, size_t capacity, size_t *length)
{
    return keyboard_config_encode(&active, output, capacity, length);
}

int keyboard_config_save(const struct keyboard_config *config)
{
    size_t length;
    ssize_t written;
    int ret;

    /* Flash programming is never allowed while the keyboard is processing HID. */
    if (!writes_allowed) { return -EACCES; }
    if (!storage.ready) { return -ENODEV; }
    k_mutex_lock(&config_store_lock, K_FOREVER);
    ret = keyboard_config_encode(config, blob, sizeof(blob), &length);
    if (ret == 0) {
        written = nvs_write(&storage, CONFIG_RECORD_ID, blob, length);
        ret = written < 0 ? (int)written :
            (written == 0 || written == length ? 0 : -EIO);
    }
    k_mutex_unlock(&config_store_lock);
    return ret;
}

int keyboard_config_import(const uint8_t *input, size_t length)
{
    /* Keep the candidate off small stacks and serialize all import callers. */
    static struct keyboard_config candidate;
    int ret;

    if (!writes_allowed) { return -EACCES; }
    k_mutex_lock(&config_import_lock, K_FOREVER);
    ret = keyboard_config_decode(input, length, &candidate);
    if (ret == 0) { ret = keyboard_config_save(&candidate); }
    k_mutex_unlock(&config_import_lock);
    return ret;
}
```

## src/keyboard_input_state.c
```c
#include <string.h>

#include <zephyr/kernel.h>

#include "keyboard_input_state.h"

static struct k_spinlock state_lock;
static uint8_t pressed_keys[KEYBOARD_INPUT_BITMAP_SIZE];

void keyboard_input_state_reset(void)
{
    k_spinlock_key_t key = k_spin_lock(&state_lock);

    memset(pressed_keys, 0, sizeof(pressed_keys));
    k_spin_unlock(&state_lock, key);
}

void keyboard_input_state_handle(const struct split_key_event *event)
{
    unsigned int bit;
    k_spinlock_key_t key;

    if (event == NULL || event->hand >= KEYBOARD_HAND_COUNT ||
        event->key_index >= KEYBOARD_KEY_COUNT ||
        event->type > SPLIT_KEY_EVENT_DOUBLE_TAP) {
        return;
    }
    bit = event->hand * KEYBOARD_KEY_COUNT + event->key_index;
    key = k_spin_lock(&state_lock);
    if (event->type == SPLIT_KEY_EVENT_PRESS) {
        pressed_keys[bit / 8] |= BIT(bit % 8);
    } else {
        /* A synthetic double tap is a completed gesture, not a held key. */
        pressed_keys[bit / 8] &= ~BIT(bit % 8);
    }
    k_spin_unlock(&state_lock, key);
}

void keyboard_input_state_snapshot(uint8_t output[KEYBOARD_INPUT_BITMAP_SIZE])
{
    k_spinlock_key_t key = k_spin_lock(&state_lock);

    memcpy(output, pressed_keys, sizeof(pressed_keys));
    k_spin_unlock(&state_lock, key);
}
```

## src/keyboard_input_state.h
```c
#ifndef ERGODOX_KEYBOARD_INPUT_STATE_H
#define ERGODOX_KEYBOARD_INPUT_STATE_H

#include "keyboard_layout.h"
#include "split_transport.h"

#define KEYBOARD_INPUT_BITMAP_SIZE ((KEYBOARD_HAND_COUNT * KEYBOARD_KEY_COUNT + 7) / 8)

/* ISR-safe physical state; no layout interpretation or HID processing. */
void keyboard_input_state_reset(void);
void keyboard_input_state_handle(const struct split_key_event *event);
void keyboard_input_state_snapshot(uint8_t output[KEYBOARD_INPUT_BITMAP_SIZE]);

/* Start local GPIO scanning and slave reception, exclusively for the viewer. */
int keyboard_inputs_start_configurator(void);

#endif
```
